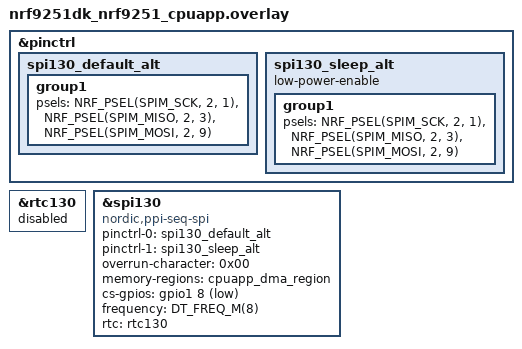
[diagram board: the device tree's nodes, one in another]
/*
 * Copyright (c) 2026 Nordic Semiconductor ASA
 *
 * SPDX-License-Identifier: LicenseRef-Nordic-5-Clause
 */

&pinctrl {
	spi130_default_alt: spi130_default_alt {
		group1 {
			psels = <NRF_PSEL(SPIM_SCK, 2, 1)>,
				<NRF_PSEL(SPIM_MISO, 2, 3)>,
				<NRF_PSEL(SPIM_MOSI, 2, 9)>;
		};
	};

	spi130_sleep_alt: spi130_sleep_alt {
		group1 {
			psels = <NRF_PSEL(SPIM_SCK, 2, 1)>,
				<NRF_PSEL(SPIM_MISO, 2, 3)>,
				<NRF_PSEL(SPIM_MOSI, 2, 9)>;
		};

		low-power-enable;
	};
};

&rtc130 {
	status = "reserved";
};

sample_spi: &spi130 {
	compatible = "nordic,ppi-seq-spi";
	status = "okay";
	pinctrl-0 = <&spi130_default_alt>;
	pinctrl-1 = <&spi130_sleep_alt>;
	pinctrl-names = "default", "sleep";
	overrun-character = <0x00>;
	memory-regions = <&cpuapp_dma_region>;
	cs-gpios = <&gpio1 8 GPIO_ACTIVE_LOW>;
	frequency = <DT_FREQ_M(8)>;
	rtc = <&rtc130>;
};
